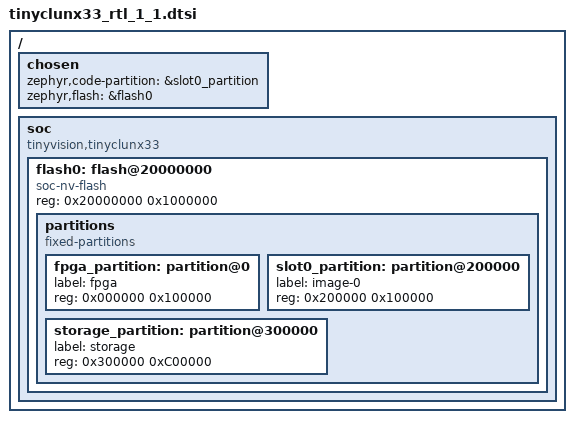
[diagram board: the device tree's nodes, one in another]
/*
 * Copyright (c) tinyVision.ai Inc.
 *
 * SPDX-License-Identifier: Apache-2.0
 */

/*
 * RTL releases that still use LiteX but with a different boot address.
 *
 * They now use 0x200000 as boot address.
 */

#include "tinyclunx33_rtl.dtsi"

/ {
	chosen {
		zephyr,code-partition = &slot0_partition;
		zephyr,flash = &flash0;
	};

	soc {
		compatible = "tinyvision,tinyclunx33";
		ranges;
		#address-cells = <1>;
		#size-cells = <1>;

		flash0: flash@20000000 {
			compatible = "soc-nv-flash";
			reg = <0x20000000 0x1000000>;
		};
	};
};

&flash0 {
	partitions {
		compatible = "fixed-partitions";
		#address-cells = <1>;
		#size-cells = <1>;

		fpga_partition: partition@0 {
			label = "fpga";
			reg = <0x000000 0x100000>;
		};

		slot0_partition: partition@200000 {
			label = "image-0";
			reg = <0x200000 0x100000>;
		};

		storage_partition: partition@300000 {
			label = "storage";
			reg = <0x300000 0xC00000>;
		};
	};
};
